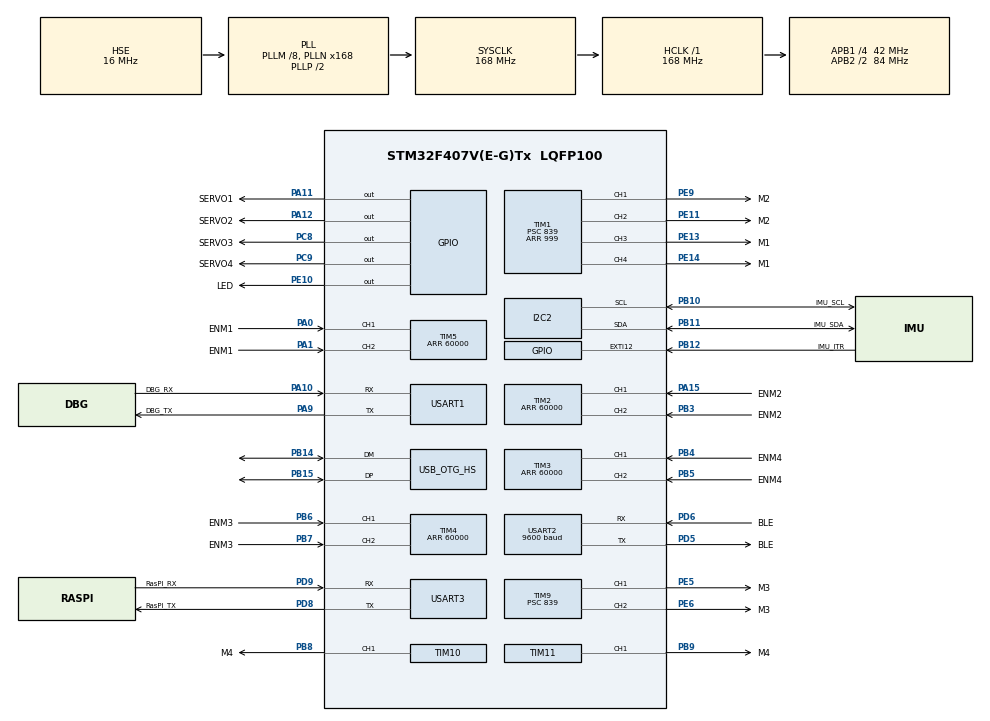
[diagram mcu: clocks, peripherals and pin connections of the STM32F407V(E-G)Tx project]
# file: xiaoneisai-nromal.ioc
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Dma.I2C2_RX.2.Direction=DMA_PERIPH_TO_MEMORY
Dma.I2C2_RX.2.FIFOMode=DMA_FIFOMODE_DISABLE
Dma.I2C2_RX.2.Instance=DMA1_Stream2
Dma.I2C2_RX.2.MemDataAlignment=DMA_MDATAALIGN_BYTE
Dma.I2C2_RX.2.MemInc=DMA_MINC_ENABLE
Dma.I2C2_RX.2.Mode=DMA_NORMAL
Dma.I2C2_RX.2.PeriphDataAlignment=DMA_PDATAALIGN_BYTE
Dma.I2C2_RX.2.PeriphInc=DMA_PINC_DISABLE
Dma.I2C2_RX.2.Priority=DMA_PRIORITY_LOW
Dma.I2C2_TX.3.Direction=DMA_MEMORY_TO_PERIPH
Dma.I2C2_TX.3.FIFOMode=DMA_FIFOMODE_DISABLE
Dma.I2C2_TX.3.Instance=DMA1_Stream7
Dma.I2C2_TX.3.MemDataAlignment=DMA_MDATAALIGN_BYTE
Dma.I2C2_TX.3.MemInc=DMA_MINC_ENABLE
Dma.I2C2_TX.3.Mode=DMA_NORMAL
Dma.I2C2_TX.3.PeriphDataAlignment=DMA_PDATAALIGN_BYTE
Dma.I2C2_TX.3.PeriphInc=DMA_PINC_DISABLE
Dma.I2C2_TX.3.Priority=DMA_PRIORITY_LOW
Dma.Request0=USART2_RX
Dma.Request1=USART2_TX
Dma.Request2=I2C2_RX
Dma.Request3=I2C2_TX
Dma.Request4=USART1_RX
Dma.Request5=USART1_TX
Dma.Request6=USART3_RX
Dma.Request7=USART3_TX
Dma.USART1_RX.4.Direction=DMA_PERIPH_TO_MEMORY
Dma.USART1_RX.4.FIFOMode=DMA_FIFOMODE_DISABLE
Dma.USART1_RX.4.Instance=DMA2_Stream2
Dma.USART1_RX.4.MemDataAlignment=DMA_MDATAALIGN_BYTE
Dma.USART1_RX.4.MemInc=DMA_MINC_ENABLE
Dma.USART1_RX.4.Mode=DMA_NORMAL
Dma.USART1_RX.4.PeriphDataAlignment=DMA_PDATAALIGN_BYTE
Dma.USART1_RX.4.PeriphInc=DMA_PINC_DISABLE
Dma.USART1_RX.4.Priority=DMA_PRIORITY_LOW
Dma.USART1_TX.5.Direction=DMA_MEMORY_TO_PERIPH
Dma.USART1_TX.5.FIFOMode=DMA_FIFOMODE_DISABLE
Dma.USART1_TX.5.Instance=DMA2_Stream7
Dma.USART1_TX.5.MemDataAlignment=DMA_MDATAALIGN_BYTE
Dma.USART1_TX.5.MemInc=DMA_MINC_ENABLE
Dma.USART1_TX.5.Mode=DMA_NORMAL
Dma.USART1_TX.5.PeriphDataAlignment=DMA_PDATAALIGN_BYTE
Dma.USART1_TX.5.PeriphInc=DMA_PINC_DISABLE
Dma.USART1_TX.5.Priority=DMA_PRIORITY_LOW
Dma.USART2_RX.0.Direction=DMA_PERIPH_TO_MEMORY
Dma.USART2_RX.0.FIFOMode=DMA_FIFOMODE_DISABLE
Dma.USART2_RX.0.Instance=DMA1_Stream5
Dma.USART2_RX.0.MemDataAlignment=DMA_MDATAALIGN_BYTE
Dma.USART2_RX.0.MemInc=DMA_MINC_ENABLE
Dma.USART2_RX.0.Mode=DMA_NORMAL
Dma.USART2_RX.0.PeriphDataAlignment=DMA_PDATAALIGN_BYTE
Dma.USART2_RX.0.PeriphInc=DMA_PINC_DISABLE
Dma.USART2_RX.0.Priority=DMA_PRIORITY_LOW
Dma.USART2_TX.1.Direction=DMA_MEMORY_TO_PERIPH
Dma.USART2_TX.1.FIFOMode=DMA_FIFOMODE_DISABLE
Dma.USART2_TX.1.Instance=DMA1_Stream6
Dma.USART2_TX.1.MemDataAlignment=DMA_MDATAALIGN_BYTE
Dma.USART2_TX.1.MemInc=DMA_MINC_ENABLE
Dma.USART2_TX.1.Mode=DMA_NORMAL
Dma.USART2_TX.1.PeriphDataAlignment=DMA_PDATAALIGN_BYTE
Dma.USART2_TX.1.PeriphInc=DMA_PINC_DISABLE
Dma.USART2_TX.1.Priority=DMA_PRIORITY_LOW
Dma.USART3_RX.6.Direction=DMA_PERIPH_TO_MEMORY
Dma.USART3_RX.6.FIFOMode=DMA_FIFOMODE_DISABLE
Dma.USART3_RX.6.Instance=DMA1_Stream1
Dma.USART3_RX.6.MemDataAlignment=DMA_MDATAALIGN_BYTE
Dma.USART3_RX.6.MemInc=DMA_MINC_ENABLE
Dma.USART3_RX.6.Mode=DMA_NORMAL
Dma.USART3_RX.6.PeriphDataAlignment=DMA_PDATAALIGN_BYTE
Dma.USART3_RX.6.PeriphInc=DMA_PINC_DISABLE
Dma.USART3_RX.6.Priority=DMA_PRIORITY_LOW
Dma.USART3_TX.7.Direction=DMA_MEMORY_TO_PERIPH
Dma.USART3_TX.7.FIFOMode=DMA_FIFOMODE_DISABLE
Dma.USART3_TX.7.Instance=DMA1_Stream3
Dma.USART3_TX.7.MemDataAlignment=DMA_MDATAALIGN_BYTE
Dma.USART3_TX.7.MemInc=DMA_MINC_ENABLE
Dma.USART3_TX.7.Mode=DMA_NORMAL
Dma.USART3_TX.7.PeriphDataAlignment=DMA_PDATAALIGN_BYTE
Dma.USART3_TX.7.PeriphInc=DMA_PINC_DISABLE
Dma.USART3_TX.7.Priority=DMA_PRIORITY_LOW
FREERTOS.BinarySemaphores01=IMU_data_ready,Dynamic,NULL,Depleted
FREERTOS.Queues01=moving_ctrl_queue,32,char,0,Static,moving_ctrl_queueBuffer,moving_ctrl_queueControlBlock
FREERTOS.Tasks01=defaultTask,24,128,StartDefaultTask,Default,NULL,Dynamic,NULL,NULL;led,8,128,led_task,As external,NULL,Dynamic,NULL,NULL;IMU,8,512,IMU_task,As external,NULL,Dynamic,NULL,NULL;app_task,24,512,app_task_entry,As external,NULL,Static,app_taskBuffer,app_taskControlBlock
Mcu.Family=STM32F4
Mcu.Name=STM32F407V(E-G)Tx
Mcu.Package=LQFP100
NVIC.DMA1_Stream1_IRQn=true\:5\:0\:false\:false\:true\:true\:false\:true\:true
NVIC.DMA1_Stream2_IRQn=true\:5\:0\:false\:false\:true\:true\:false\:true\:true
NVIC.DMA1_Stream3_IRQn=true\:5\:0\:false\:false\:true\:true\:false\:true\:true
NVIC.DMA1_Stream5_IRQn=true\:5\:0\:false\:false\:true\:true\:false\:true\:true
NVIC.DMA1_Stream6_IRQn=true\:5\:0\:false\:false\:true\:true\:false\:true\:true
NVIC.DMA1_Stream7_IRQn=true\:5\:0\:false\:false\:true\:true\:false\:true\:true
NVIC.DMA2_Stream2_IRQn=true\:5\:0\:false\:false\:true\:true\:false\:true\:true
NVIC.DMA2_Stream7_IRQn=true\:5\:0\:false\:false\:true\:true\:false\:true\:true
NVIC.EXTI15_10_IRQn=true\:5\:0\:false\:false\:true\:true\:true\:true\:true
NVIC.I2C2_ER_IRQn=true\:5\:0\:false\:false\:true\:true\:true\:true\:true
NVIC.I2C2_EV_IRQn=true\:5\:0\:false\:false\:true\:true\:true\:true\:true
NVIC.OTG_HS_IRQn=true\:5\:0\:false\:false\:true\:true\:true\:true\:true
NVIC.PriorityGroup=NVIC_PRIORITYGROUP_4
NVIC.TIM1_BRK_TIM9_IRQn=true\:5\:0\:false\:false\:true\:true\:true\:true\:true
NVIC.TIM1_CC_IRQn=true\:5\:0\:false\:false\:true\:true\:true\:true\:true
NVIC.TIM1_TRG_COM_TIM11_IRQn=true\:5\:0\:false\:false\:true\:true\:true\:true\:true
NVIC.TIM1_UP_TIM10_IRQn=true\:5\:0\:false\:false\:true\:true\:true\:true\:true
NVIC.TIM2_IRQn=true\:5\:0\:false\:false\:true\:true\:true\:true\:true
NVIC.TIM3_IRQn=true\:5\:0\:false\:false\:true\:true\:true\:true\:true
NVIC.TIM4_IRQn=true\:5\:0\:false\:false\:true\:true\:true\:true\:true
NVIC.TIM5_IRQn=true\:5\:0\:false\:false\:true\:true\:true\:true\:true
NVIC.TIM7_IRQn=true\:5\:0\:false\:false\:true\:true\:true\:true\:true
NVIC.TIM8_BRK_TIM12_IRQn=true\:5\:0\:false\:false\:true\:true\:true\:true\:true
NVIC.TIM8_TRG_COM_TIM14_IRQn=true\:15\:0\:false\:false\:true\:false\:false\:true\:true
NVIC.TIM8_UP_TIM13_IRQn=true\:5\:0\:false\:false\:true\:true\:true\:true\:true
NVIC.TimeBase=TIM8_TRG_COM_TIM14_IRQn
NVIC.TimeBaseIP=TIM14
NVIC.USART1_IRQn=true\:5\:0\:false\:false\:true\:true\:true\:true\:true
NVIC.USART2_IRQn=true\:5\:0\:false\:false\:true\:true\:true\:true\:true
NVIC.USART3_IRQn=true\:5\:0\:false\:false\:true\:true\:true\:true\:true
PA0-WKUP.GPIO_Label=ENM1
PA0-WKUP.Signal=S_TIM5_CH1
PA1.GPIO_Label=ENM1
PA1.Signal=S_TIM5_CH2
PA10.GPIO_Label=DBG_RX
PA10.Mode=Asynchronous
PA10.Signal=USART1_RX
PA11.GPIO_Label=SERVO1
PA11.Signal=GPIO_Output
PA12.GPIO_Label=SERVO2
PA12.Signal=GPIO_Output
PA13.Mode=Serial_Wire
PA13.Signal=SYS_JTMS-SWDIO
PA14.Mode=Serial_Wire
PA14.Signal=SYS_JTCK-SWCLK
PA15.GPIO_Label=ENM2
PA15.Signal=S_TIM2_CH1_ETR
PA9.GPIO_Label=DBG_TX
PA9.Mode=Asynchronous
PA9.Signal=USART1_TX
PB10.GPIO_Label=IMU_SCL
PB10.Mode=I2C
PB10.Signal=I2C2_SCL
PB11.GPIO_Label=IMU_SDA
PB11.Mode=I2C
PB11.Signal=I2C2_SDA
PB12.GPIO_Label=IMU_ITR
PB12.Signal=GPXTI12
PB14.Mode=Host_FS
PB14.Signal=USB_OTG_HS_DM
PB15.Mode=Host_FS
PB15.Signal=USB_OTG_HS_DP
PB3.GPIO_Label=ENM2
PB3.Signal=S_TIM2_CH2
PB4.GPIO_Label=ENM4
PB4.Signal=S_TIM3_CH1
PB5.GPIO_Label=ENM4
PB5.Signal=S_TIM3_CH2
PB6.GPIO_Label=ENM3
PB6.Signal=S_TIM4_CH1
PB7.GPIO_Label=ENM3
PB7.Signal=S_TIM4_CH2
PB8.GPIO_Label=M4
PB8.Signal=S_TIM10_CH1
PB9.GPIO_Label=M4
PB9.Signal=S_TIM11_CH1
PC8.GPIO_Label=SERVO3
PC8.Signal=GPIO_Output
PC9.GPIO_Label=SERVO4
PC9.Signal=GPIO_Output
PD5.GPIO_Label=BLE
PD5.Mode=Asynchronous
PD5.Signal=USART2_TX
PD6.GPIO_Label=BLE
PD6.Mode=Asynchronous
PD6.Signal=USART2_RX
PD8.GPIO_Label=RasPI_TX
PD8.Mode=Asynchronous
PD8.Signal=USART3_TX
PD9.GPIO_Label=RasPI_RX
PD9.Mode=Asynchronous
PD9.Signal=USART3_RX
PE10.GPIO_Label=LED
PE10.Signal=GPIO_Output
PE11.GPIO_Label=M2
PE11.Signal=S_TIM1_CH2
PE13.GPIO_Label=M1
PE13.Signal=S_TIM1_CH3
PE14.GPIO_Label=M1
PE14.Signal=S_TIM1_CH4
PE5.GPIO_Label=M3
PE5.Signal=S_TIM9_CH1
PE6.GPIO_Label=M3
PE6.Signal=S_TIM9_CH2
PE9.GPIO_Label=M2
PE9.Signal=S_TIM1_CH1
PH0-OSC_IN.Mode=HSE-External-Oscillator
PH0-OSC_IN.Signal=RCC_OSC_IN
PH1-OSC_OUT.Mode=HSE-External-Oscillator
PH1-OSC_OUT.Signal=RCC_OSC_OUT
ProjectManager.HeapSize=0x200
ProjectManager.StackSize=0x400
ProjectManager.TargetToolchain=CMake
RCC.48MHZClocksFreq_Value=48000000
RCC.AHBFreq_Value=168000000
RCC.APB1CLKDivider=RCC_HCLK_DIV4
RCC.APB1Freq_Value=42000000
RCC.APB1TimFreq_Value=84000000
RCC.APB2CLKDivider=RCC_HCLK_DIV2
RCC.APB2Freq_Value=84000000
RCC.APB2TimFreq_Value=168000000
RCC.CortexFreq_Value=168000000
RCC.HCLKFreq_Value=168000000
RCC.HSE_VALUE=16000000
RCC.HSI_VALUE=16000000
RCC.LSE_VALUE=32768
RCC.PLLM=8
RCC.PLLN=168
RCC.PLLQ=7
RCC.SYSCLKFreq_VALUE=168000000
RCC.SYSCLKSource=RCC_SYSCLKSOURCE_PLLCLK
RCC.VCOOutputFreq_Value=336000000
SH.S_TIM10_CH1.0=TIM10_CH1,PWM Generation1 CH1
SH.S_TIM11_CH1.0=TIM11_CH1,PWM Generation1 CH1
SH.S_TIM1_CH1.0=TIM1_CH1,PWM Generation1 CH1
SH.S_TIM1_CH2.0=TIM1_CH2,PWM Generation2 CH2
SH.S_TIM1_CH3.0=TIM1_CH3,PWM Generation3 CH3
SH.S_TIM1_CH4.0=TIM1_CH4,Output Compare4 CH4
SH.S_TIM2_CH1_ETR.0=TIM2_CH1,Encoder_Interface
SH.S_TIM2_CH2.0=TIM2_CH2,Encoder_Interface
SH.S_TIM3_CH1.0=TIM3_CH1,Encoder_Interface
SH.S_TIM3_CH2.0=TIM3_CH2,Encoder_Interface
SH.S_TIM4_CH1.0=TIM4_CH1,Encoder_Interface
SH.S_TIM4_CH2.0=TIM4_CH2,Encoder_Interface
SH.S_TIM5_CH1.0=TIM5_CH1,Encoder_Interface
SH.S_TIM5_CH2.0=TIM5_CH2,Encoder_Interface
SH.S_TIM9_CH1.0=TIM9_CH1,PWM Generation1 CH1
SH.S_TIM9_CH2.0=TIM9_CH2,PWM Generation2 CH2
TIM1.AutoReloadPreload=TIM_AUTORELOAD_PRELOAD_ENABLE
TIM1.Channel-Output\ Compare4\ CH4=TIM_CHANNEL_4
TIM1.Channel-PWM\ Generation1\ CH1=TIM_CHANNEL_1
TIM1.Channel-PWM\ Generation2\ CH2=TIM_CHANNEL_2
TIM1.Channel-PWM\ Generation3\ CH3=TIM_CHANNEL_3
TIM1.Period=999
TIM1.Prescaler=839
TIM10.AutoReloadPreload=TIM_AUTORELOAD_PRELOAD_ENABLE
TIM10.Channel=TIM_CHANNEL_1
TIM10.Period=999
TIM10.Prescaler=839
TIM11.AutoReloadPreload=TIM_AUTORELOAD_PRELOAD_ENABLE
TIM11.Channel=TIM_CHANNEL_1
TIM11.Period=999
TIM11.Prescaler=839
TIM12.Channel-Output\ Compare1\ No\ Output=TIM_CHANNEL_1
TIM12.Prescaler=839
TIM13.AutoReloadPreload=TIM_AUTORELOAD_PRELOAD_ENABLE
TIM13.Channel=TIM_CHANNEL_1
TIM13.OC1Preload=ENABLE
TIM13.Period=4999
TIM13.Prescaler=83
TIM2.EncoderMode=TIM_ENCODERMODE_TI12
TIM2.Period=60000
TIM3.EncoderMode=TIM_ENCODERMODE_TI12
TIM3.Period=60000
TIM4.EncoderMode=TIM_ENCODERMODE_TI12
TIM4.Period=60000
TIM5.EncoderMode=TIM_ENCODERMODE_TI12
TIM5.Period=60000
TIM7.Prescaler=83
TIM9.AutoReloadPreload=TIM_AUTORELOAD_PRELOAD_ENABLE
TIM9.Channel-PWM\ Generation1\ CH1=TIM_CHANNEL_1
TIM9.Channel-PWM\ Generation2\ CH2=TIM_CHANNEL_2
TIM9.Period=999
TIM9.Prescaler=839
USART1.VirtualMode=VM_ASYNC
USART2.BaudRate=9600
USART2.VirtualMode=VM_ASYNC
USART3.VirtualMode=VM_ASYNC
USB_HOST.USBH_HandleTypeDef-HID_HS=hUsbHostHS
USB_HOST.USBH_MAX_NUM_CONFIGURATION-HID_HS=2
USB_HOST.USBH_MAX_SIZE_CONFIGURATION-HID_HS=512
USB_HOST.USBH_PROCESS_STACK_SIZE-HID_HS=2048
USB_HOST.VirtualModeHS=Hid
USB_OTG_HS.VirtualMode-Host_FS=Host_FS
VP_FREERTOS_VS_CMSIS_V2.Mode=CMSIS_V2
VP_SYS_VS_tim14.Mode=TIM14
VP_TIM10_VS_ClockSourceINT.Mode=Enable_Timer
VP_TIM11_VS_ClockSourceINT.Mode=Enable_Timer
VP_TIM12_VS_no_output1.Mode=Output Compare1 No Output
VP_TIM13_VS_ClockSourceINT.Mode=Enable_Timer
VP_TIM13_VS_no_output1.Mode=Output Compare1 No Output
VP_TIM1_VS_ClockSourceINT.Mode=Internal
VP_TIM7_VS_ClockSourceINT.Mode=Enable_Timer
VP_TIM9_VS_ClockSourceINT.Mode=Internal
VP_USB_HOST_VS_USB_HOST_HID_HS.Mode=HID_HS
board=custom

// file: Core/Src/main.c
/* USER CODE BEGIN Header */
/**
  ******************************************************************************
  * @file           : main.c
  * @brief          : Main program body
  ******************************************************************************
  * @attention
  *
  * Copyright (c) 2025 STMicroelectronics.
  * All rights reserved.
  *
  * This software is licensed under terms that can be found in the LICENSE file
  * in the root directory of this software component.
  * If no LICENSE file comes with this software, it is provided AS-IS.
  *
  ******************************************************************************
  */
/* USER CODE END Header */
#include "main.h"
#include "cmsis_os.h"
#include "dma.h"
#include "i2c.h"
#include "tim.h"
#include "usart.h"
#include "usb_host.h"
#include "gpio.h"

/* USER CODE BEGIN Includes */
#include "pwm_servo.h"
/* USER CODE END Includes */

/* USER CODE BEGIN PV */
extern uint8_t receiveBLEData[64];
extern uint8_t receivePIData[64];
extern osMessageQueueId_t moving_ctrl_queueHandle;
/* USER CODE END PV */

void SystemClock_Config(void);
void MX_FREERTOS_Init(void);
/* USER CODE BEGIN PFP */
extern void motors_init(void);
extern void chassis_init(void);
/* USER CODE END PFP */

int main(void)
{

  /* MCU Configuration--------------------------------------------------------*/

  /* Reset of all peripherals, Initializes the Flash interface and the Systick. */
  HAL_Init();

  /* Configure the system clock */
  SystemClock_Config();

  /* Initialize all configured peripherals */
  MX_GPIO_Init();
  MX_DMA_Init();
  MX_USART2_UART_Init();
  MX_TIM1_Init();
  MX_TIM9_Init();
  MX_TIM10_Init();
  MX_TIM11_Init();
  MX_TIM13_Init();
  MX_I2C2_Init();
  MX_TIM5_Init();
  MX_TIM2_Init();
  MX_TIM3_Init();
  MX_TIM4_Init();
  MX_TIM7_Init();
  MX_TIM12_Init();
  MX_USART1_UART_Init();
  MX_USART3_UART_Init();
  /* USER CODE BEGIN 2 */
  HAL_UARTEx_ReceiveToIdle_DMA(&huart2, receiveBLEData, sizeof(receiveBLEData));
  HAL_UARTEx_ReceiveToIdle_DMA(&huart3, receivePIData, sizeof(receivePIData));
  pwm_servos_init();
  motors_init();
  osMessageQueueReset(moving_ctrl_queueHandle);
  chassis_init();
  /* USER CODE END 2 */

  /* Init scheduler */
  osKernelInitialize();

  /* Call init function for freertos objects (in cmsis_os2.c) */
  MX_FREERTOS_Init();

  /* Start scheduler */
  osKernelStart();

  /* We should never get here as control is now taken by the scheduler */

  /* Infinite loop */
  /* USER CODE BEGIN WHILE */
  //开了freertos,此while不可用了
  while (1)
  {
    /* USER CODE END WHILE */

  }
}

void SystemClock_Config(void)
{
  RCC_OscInitTypeDef RCC_OscInitStruct = {0};
  RCC_ClkInitTypeDef RCC_ClkInitStruct = {0};

  /** Configure the main internal regulator output voltage
  */
  __HAL_RCC_PWR_CLK_ENABLE();
  __HAL_PWR_VOLTAGESCALING_CONFIG(PWR_REGULATOR_VOLTAGE_SCALE1);

  /** Initializes the RCC Oscillators according to the specified parameters
  * in the RCC_OscInitTypeDef structure.
  */
  RCC_OscInitStruct.OscillatorType = RCC_OSCILLATORTYPE_HSE;
  RCC_OscInitStruct.HSEState = RCC_HSE_ON;
  RCC_OscInitStruct.PLL.PLLState = RCC_PLL_ON;
  RCC_OscInitStruct.PLL.PLLSource = RCC_PLLSOURCE_HSE;
  RCC_OscInitStruct.PLL.PLLM = 8;
  RCC_OscInitStruct.PLL.PLLN = 168;
  RCC_OscInitStruct.PLL.PLLP = RCC_PLLP_DIV2;
  RCC_OscInitStruct.PLL.PLLQ = 7;
  if (HAL_RCC_OscConfig(&RCC_OscInitStruct) != HAL_OK)
  {
    Error_Handler();
  }

  /** Initializes the CPU, AHB and APB buses clocks
  */
  RCC_ClkInitStruct.ClockType = RCC_CLOCKTYPE_HCLK|RCC_CLOCKTYPE_SYSCLK
                              |RCC_CLOCKTYPE_PCLK1|RCC_CLOCKTYPE_PCLK2;
  RCC_ClkInitStruct.SYSCLKSource = RCC_SYSCLKSOURCE_PLLCLK;
  RCC_ClkInitStruct.AHBCLKDivider = RCC_SYSCLK_DIV1;
  RCC_ClkInitStruct.APB1CLKDivider = RCC_HCLK_DIV4;
  RCC_ClkInitStruct.APB2CLKDivider = RCC_HCLK_DIV2;

  if (HAL_RCC_ClockConfig(&RCC_ClkInitStruct, FLASH_LATENCY_5) != HAL_OK)
  {
    Error_Handler();
  }
}

void HAL_TIM_PeriodElapsedCallback(TIM_HandleTypeDef *htim)
{
  if (htim->Instance == TIM14)
  {
    HAL_IncTick();
  }
}

void Error_Handler(void)
{
  __disable_irq();
  while (1)
  {
  }
}

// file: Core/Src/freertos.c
/* USER CODE BEGIN Header */
/**
  ******************************************************************************
  * File Name          : freertos.c
  * Description        : Code for freertos applications
  ******************************************************************************
  * @attention
  *
  * Copyright (c) 2025 STMicroelectronics.
  * All rights reserved.
  *
  * This software is licensed under terms that can be found in the LICENSE file
  * in the root directory of this software component.
  * If no LICENSE file comes with this software, it is provided AS-IS.
  *
  ******************************************************************************
  */
/* USER CODE END Header */

#include "FreeRTOS.h"
#include "task.h"
#include "main.h"
#include "cmsis_os.h"

typedef StaticTask_t osStaticThreadDef_t;
typedef StaticQueue_t osStaticMessageQDef_t;

/* Definitions for defaultTask */
osThreadId_t defaultTaskHandle;
const osThreadAttr_t defaultTask_attributes = {
  .name = "defaultTask",
  .stack_size = 128 * 4,
  .priority = (osPriority_t) osPriorityNormal,
};
/* Definitions for led */
osThreadId_t ledHandle;
const osThreadAttr_t led_attributes = {
  .name = "led",
  .stack_size = 128 * 4,
  .priority = (osPriority_t) osPriorityLow,
};
/* Definitions for IMU */
osThreadId_t IMUHandle;
const osThreadAttr_t IMU_attributes = {
  .name = "IMU",
  .stack_size = 512 * 4,
  .priority = (osPriority_t) osPriorityLow,
};
/* Definitions for app_task */
osThreadId_t app_taskHandle;
uint32_t app_taskBuffer[ 512 ];
osStaticThreadDef_t app_taskControlBlock;
const osThreadAttr_t app_task_attributes = {
  .name = "app_task",
  .cb_mem = &app_taskControlBlock,
  .cb_size = sizeof(app_taskControlBlock),
  .stack_mem = &app_taskBuffer[0],
  .stack_size = sizeof(app_taskBuffer),
  .priority = (osPriority_t) osPriorityNormal,
};
/* Definitions for moving_ctrl_queue */
osMessageQueueId_t moving_ctrl_queueHandle;
uint8_t moving_ctrl_queueBuffer[ 32 * sizeof( char ) ];
osStaticMessageQDef_t moving_ctrl_queueControlBlock;
const osMessageQueueAttr_t moving_ctrl_queue_attributes = {
  .name = "moving_ctrl_queue",
  .cb_mem = &moving_ctrl_queueControlBlock,
  .cb_size = sizeof(moving_ctrl_queueControlBlock),
  .mq_mem = &moving_ctrl_queueBuffer,
  .mq_size = sizeof(moving_ctrl_queueBuffer)
};
/* Definitions for IMU_data_ready */
osSemaphoreId_t IMU_data_readyHandle;
const osSemaphoreAttr_t IMU_data_ready_attributes = {
  .name = "IMU_data_ready"
};

void StartDefaultTask(void *argument);
extern void led_task(void *argument);
extern void IMU_task(void *argument);
extern void app_task_entry(void *argument);

extern void MX_USB_HOST_Init(void);
void MX_FREERTOS_Init(void); /* (MISRA C 2004 rule 8.1) */

void MX_FREERTOS_Init(void) {

  /* Create the semaphores(s) */
  /* creation of IMU_data_ready */
  IMU_data_readyHandle = osSemaphoreNew(1, 0, &IMU_data_ready_attributes);

  /* Create the queue(s) */
  /* creation of moving_ctrl_queue */
  moving_ctrl_queueHandle = osMessageQueueNew (32, sizeof(char), &moving_ctrl_queue_attributes);

  /* Create the thread(s) */
  /* creation of defaultTask */
  defaultTaskHandle = osThreadNew(StartDefaultTask, NULL, &defaultTask_attributes);

  /* creation of led */
  ledHandle = osThreadNew(led_task, NULL, &led_attributes);

  /* creation of IMU */
  IMUHandle = osThreadNew(IMU_task, NULL, &IMU_attributes);

  /* creation of app_task */
  app_taskHandle = osThreadNew(app_task_entry, NULL, &app_task_attributes);

}

void StartDefaultTask(void *argument)
{
  /* init code for USB_HOST */
  MX_USB_HOST_Init();
  for(;;)
  {
    osDelay(1);
  }
}
